# AT32F423xx_v2 register map
Vendor: Keil; Series: AT32F423; File version: 1.0
CPU: CM4 r0p1, little endian, no MPU, FPU, 4 interrupt priority bits
Registers are 32-bit, read-write, reset 0x0 unless marked. A register's access mark holds for its fields unless they carry their own. Offsets are from the block's base; [hi:lo] are bit positions.

## USART1 — Universal synchronous asynchronous receiver transmitter
Base 0x40011000
Same registers: USART2 0x40004400, USART3 0x40004800, USART4 0x40004C00, USART5 0x40005000, USART7 0x40007800, USART8 0x40007C00, USART6 0x40011400
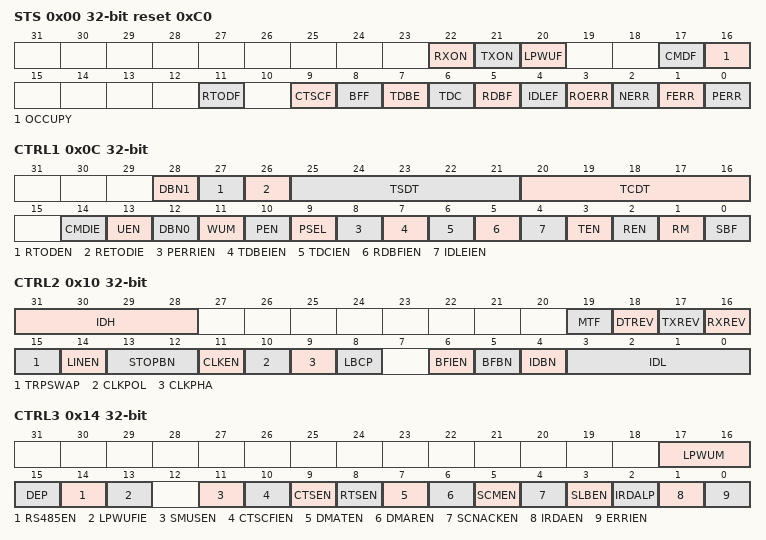
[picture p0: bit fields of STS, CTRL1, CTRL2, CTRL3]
0x00 STS reset 0xC0 — Status register
  [22] RXON ro — Receiver enabled flag
  [21] TXON ro — Transmitter enabled flag
  [20] LPWUF ro — Low power wakeup flag
  [17] CMDF ro — Character match detect flag
  [16] OCCUPY ro — Receiver occupied flag
  [11] RTODF ro — Receiver time out detection flag
  [9] CTSCF — CTS change flag
  [8] BFF — Break frame flag
  [7] TDBE ro — Transmit data buffer empty
  [6] TDC — Transmit data complete
  [5] RDBF — Receive data buffer full
  [4] IDLEF ro — IDLE flag
  [3] ROERR ro — Receiver overflow error
  [2] NERR ro — Noise error
  [1] FERR ro — Framing error
  [0] PERR ro — Parity error
0x04 DT — Data register
  [8:0] DT — Data value
0x08 BAUDR — Baud rate register
  [15:0] DIV — Division
0x0C CTRL1 — Control register 1
  [28] DBN1 — high bit for Data bit num
  [27] RTODEN — Receiver time out detection enable
  [26] RETODIE — Receiver time out detection interrupt enable
  [25:21] TSDT — transmit start delay time
  [20:16] TCDT — transmit complete delay time
  [14] CMDIE — Character match detection interrupt enable
  [13] UEN — USART enable
  [12] DBN0 — low bit for Data bit num
  [11] WUM — Wake up mode
  [10] PEN — Parity enable
  [9] PSEL — Parity selection
  [8] PERRIEN — PERR interrupt enable
  [7] TDBEIEN — TDBE interrupt enable
  [6] TDCIEN — TDC interrupt enable
  [5] RDBFIEN — RDBF interrupt enable
  [4] IDLEIEN — IDLE interrupt enable
  [3] TEN — Transmitter enable
  [2] REN — Receiver enable
  [1] RM — Receiver mute
  [0] SBF — Send break frame
0x10 CTRL2 — Control register 2
  [31:28] IDH — bit 7-4 for usart identification
  [19] MTF — MSB transmit first
  [18] DTREV — DT register polarity reverse
  [17] TXREV — TX polarity reverse
  [16] RXREV — RX polarity reverse
  [15] TRPSWAP — Transmit receive pin swap
  [14] LINEN — LIN mode enable
  [13:12] STOPBN — STOP bit num
  [11] CLKEN — Clock enable
  [10] CLKPOL — Clock polarity
  [9] CLKPHA — Clock phase
  [8] LBCP — Last bit clock pulse
  [6] BFIEN — Break frame interrupt enable
  [5] BFBN — Break frame bit num
  [4] IDBN — Identification bit num
  [3:0] IDL — bit 3-0 for usart identification
0x14 CTRL3 — Control register 3
  [17:16] LPWUM — Low power wakeup method
  [15] DEP — DE polarity selection
  [14] RS485EN — RS485 enable
  [13] LPWUFIE — Low power wakeup flag interrupt enable
  [11] SMUSEN — Deepsleep mode usart enable
  [10] CTSCFIEN — CTSCF interrupt enable
  [9] CTSEN — CTS enable
  [8] RTSEN — RTS enable
  [7] DMATEN — DMA transmitter enable
  [6] DMAREN — DMA receiver enable
  [5] SCMEN — Smartcard mode enable
  [4] SCNACKEN — Smartcard NACK enable
  [3] SLBEN — Single line bidirectional half-duplex enable
  [2] IRDALP — IrDA low-power mode
  [1] IRDAEN — IrDA enable
  [0] ERRIEN — Error interrupt enable
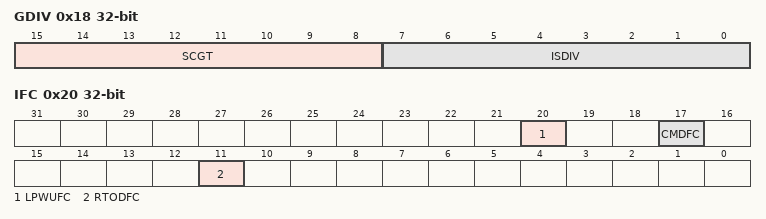
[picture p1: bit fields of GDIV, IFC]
0x18 GDIV — Guard time and division register
  [15:8] SCGT — Smart card guard time value
  [7:0] ISDIV — IrDA/smartcard division value
0x1C RTOV — Receiver time out value register
  [23:0] RTOV — Receiver time out value
0x20 IFC wo — Interrupt flag clear register
  [20] LPWUFC — Low power wake up flag clear
  [17] CMDFC — Character match flag clear
  [11] RTODFC — Receiver time out detection flag clear

## ADCCOM — ADC common area
Base 0x40012300
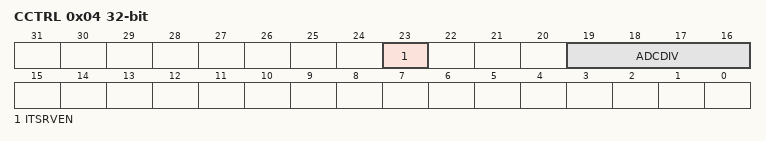
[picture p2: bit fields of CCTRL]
0x04 CCTRL — Common control register
  [23] ITSRVEN — Internal temperature sensor and VINTRV enable
  [19:16] ADCDIV — ADC division

## DAC — Digital to analog converter
Base 0x40007400
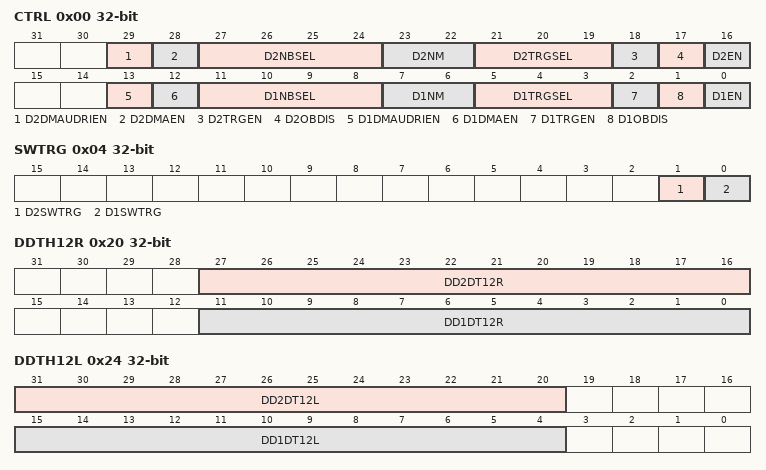
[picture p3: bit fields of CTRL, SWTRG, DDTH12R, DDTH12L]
0x00 CTRL — Control register (DAC_CTRL)
  [29] D2DMAUDRIEN — DAC2 DMA underrun interrupt enable
  [28] D2DMAEN — DAC2 DMA enable
  [27:24] D2NBSEL — DAC2 mask/amplitude selector
  [23:22] D2NM — DAC2 noise/triangle wave generation enable
  [21:19] D2TRGSEL — DAC2 trigger selection
  [18] D2TRGEN — DAC2 trigger enable
  [17] D2OBDIS — DAC2 output buffer disable
  [16] D2EN — DAC2 enable
  [13] D1DMAUDRIEN — DAC1 DMA underrun interrupt enable
  [12] D1DMAEN — DAC1 DMA enable
  [11:8] D1NBSEL — DAC1 mask/amplitude selector
  [7:6] D1NM — DAC1 noise/triangle wave generation enable
  [5:3] D1TRGSEL — DAC1 trigger selection
  [2] D1TRGEN — DAC1 trigger enable
  [1] D1OBDIS — DAC1 output buffer disable
  [0] D1EN — DAC1 enable
0x04 SWTRG wo — DAC software trigger register(DAC_SWTRIGR)
  [1] D2SWTRG — DAC2 software trigger
  [0] D1SWTRG — DAC1 software trigger
0x08 D1DTH12R — DAC1 12-bit right-aligned data holding register(DAC_D1DTH12R)
  [11:0] D1DT12R — DAC1 12-bit right-aligned data
0x0C D1DTH12L — DAC1 12-bit left aligned data holding register (DAC_D1DTH12L)
  [15:4] D1DT12L — DAC1 12-bit left-aligned data
0x10 D1DTH8R — DAC1 8-bit right aligned data holding register (DAC_D1DTH8R)
  [7:0] D1DT8R — DAC1 8-bit right-aligned data
0x14 D2DTH12R — DAC2 12-bit right aligned data holding register (DAC_D2DTH12R)
  [11:0] D2DT12R — DAC2 12-bit right-aligned data
0x18 D2DTH12L — DAC2 12-bit left aligned data holding register (DAC_D2DTH12L)
  [15:4] D2DT12L — DAC2 12-bit left-aligned data
0x1C D2DTH8R — DAC2 8-bit right-aligned data holding register (DAC_D2DTH8R)
  [7:0] D2DT8R — DAC2 8-bit right-aligned data
0x20 DDTH12R — Dual DAC 12-bit right-aligned data holding register (DAC_DDTH12R), Bits 31:28 Reserved, Bits 15:12 Reserved
  [27:16] DD2DT12R — DAC2 12-bit right-aligned data
  [11:0] DD1DT12R — DAC1 12-bit right-aligned data
0x24 DDTH12L — DUAL DAC 12-bit left aligned data holding register (DAC_DDTH12L), Bits 19:16 Reserved, Bits 3:0 Reserved
  [31:20] DD2DT12L — DAC2 12-bit right-aligned data
  [15:4] DD1DT12L — DAC1 12-bit left-aligned data
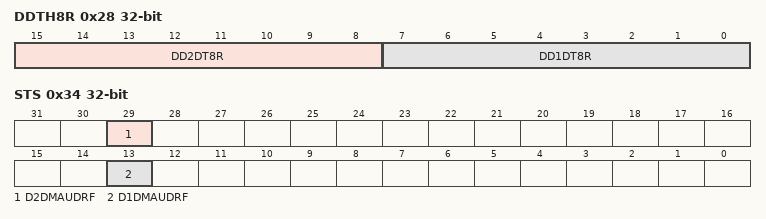
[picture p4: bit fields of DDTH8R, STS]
0x28 DDTH8R — DUAL DAC 8-bit right aligned data holding register (DAC_DDTH8R), Bits 31:16 Reserved
  [15:8] DD2DT8R — DAC2 8-bit right-aligned data
  [7:0] DD1DT8R — DAC1 8-bit right-aligned data
0x2C D1ODT ro — DAC1 data output register (DAC_D1ODT)
  [11:0] D1ODT — DAC1 data output
0x30 D2ODT ro — DAC2 data output register (DAC_D2ODT)
  [11:0] D2ODT — DAC2 data output
0x34 STS — DAC2 status register (DAC_STS)
  [29] D2DMAUDRF — DAC2 DMA underrun flag
  [13] D1DMAUDRF — DAC1 DMA underrun flag

## Notices in the file
Copyright (C) 2012-2014 ARM Limited. All rights reserved.
Purpose: System Viewer Description (SVD) Example (Schema Version 1.1)
This is a description of a none-existent and incomplete device
for demonstration purposes only.
Redistribution and use in source and binary forms, with or without
modification, are permitted provided that the following conditions are met:
- Redistributions of source code must retain the above copyright
notice, this list of conditions and the following disclaimer.
- Redistributions in binary form must reproduce the above copyright
notice, this list of conditions and the following disclaimer in the
documentation and/or other materials provided with the distribution.
- Neither the name of ARM nor the names of its contributors may be used
to endorse or promote products derived from this software without
specific prior written permission.
THIS SOFTWARE IS PROVIDED BY THE COPYRIGHT HOLDERS AND CONTRIBUTORS "AS IS"
AND ANY EXPRESS OR IMPLIED WARRANTIES, INCLUDING, BUT NOT LIMITED TO, THE
IMPLIED WARRANTIES OF MERCHANTABILITY AND FITNESS FOR A PARTICULAR PURPOSE
ARE DISCLAIMED. IN NO EVENT SHALL COPYRIGHT HOLDERS AND CONTRIBUTORS BE
LIABLE FOR ANY DIRECT, INDIRECT, INCIDENTAL, SPECIAL, EXEMPLARY, OR
CONSEQUENTIAL DAMAGES (INCLUDING, BUT NOT LIMITED TO, PROCUREMENT OF
SUBSTITUTE GOODS OR SERVICES; LOSS OF USE, DATA, OR PROFITS; OR BUSINESS
INTERRUPTION) HOWEVER CAUSED AND ON ANY THEORY OF LIABILITY, WHETHER IN
CONTRACT, STRICT LIABILITY, OR TORT (INCLUDING NEGLIGENCE OR OTHERWISE)
ARISING IN ANY WAY OUT OF THE USE OF THIS SOFTWARE, EVEN IF ADVISED OF THE
POSSIBILITY OF SUCH DAMAGE.
